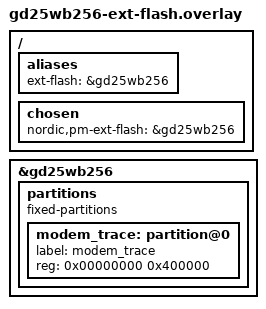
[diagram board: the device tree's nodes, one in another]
/*
 * Copyright (c) 2024 Nordic Semiconductor ASA
 *
 * SPDX-License-Identifier: LicenseRef-Nordic-5-Clause
 */

&gd25wb256 {
	status = "okay";

	partitions {
		compatible = "fixed-partitions";
		#address-cells = <1>;
		#size-cells = <1>;

		modem_trace: partition@0 {
			label = "modem_trace";
			reg = <0x00000000 0x400000>;
		};
	};
};

/ {
	aliases {
		ext-flash = &gd25wb256;
	};

	/* Configure partition manager to use gd25wb256 as the external flash */
	chosen {
		nordic,pm-ext-flash = &gd25wb256;
	};
};
